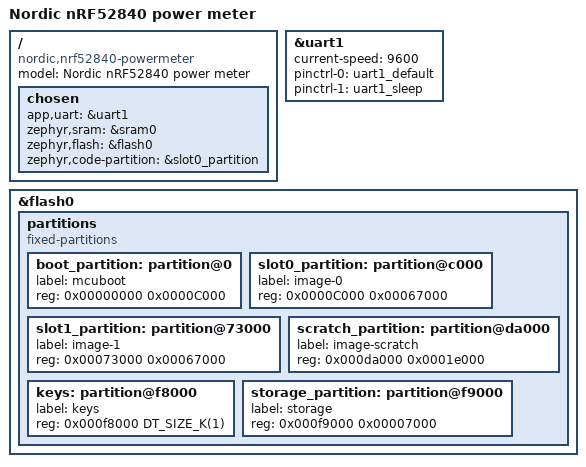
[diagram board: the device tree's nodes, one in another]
/*
 * SPDX-License-Identifier: Apache-2.0
 */

/dts-v1/;
#include <nordic/nrf52840_qiaa.dtsi>
#include "nrf52840_powermeter-pinctrl.dtsi"

/ {
	model = "Nordic nRF52840 power meter";
	compatible = "nordic,nrf52840-powermeter";

	chosen {
		app,uart = &uart1;
		zephyr,sram = &sram0;
		zephyr,flash = &flash0;
		zephyr,code-partition = &slot0_partition;
	};
};

&uart1 {
	status = "okay";
	current-speed = <9600>;
	pinctrl-0 = <&uart1_default>;
	pinctrl-1 = <&uart1_sleep>;
	pinctrl-names = "default", "sleep";
};

&flash0 {

	partitions {
		compatible = "fixed-partitions";
		#address-cells = <1>;
		#size-cells = <1>;

		boot_partition: partition@0 {
			label = "mcuboot";
			reg = <0x00000000 0x0000C000>;
		};
		slot0_partition: partition@c000 {
			label = "image-0";
			reg = <0x0000C000 0x00067000>;
		};
		slot1_partition: partition@73000 {
			label = "image-1";
			reg = <0x00073000 0x00067000>;
		};
		scratch_partition: partition@da000 {
			label = "image-scratch";
			reg = <0x000da000 0x0001e000>;
		};

		keys: partition@f8000 {
			label = "keys";
			reg = <0x000f8000 DT_SIZE_K(1)>;
		};

		storage_partition: partition@f9000 {
			label = "storage";
			reg = <0x000f9000 0x00007000>;
		};
	};
};
